# PIC16F15276 register map
File version: 1.0
PIC16F15276 special function registers
Registers are 8-bit, read-write, reset 0x0 unless marked. A register's access mark holds for its fields unless they carry their own. Offsets are from the block's base; lines under a group give offsets from that group; [hi:lo] are bit positions; {n}, {i} and the like mark numbered series; 'fields as' and 'values as' point back to an identical list; <NAME> marks a mode.

## Memory map
0x00800000 CPU size 0x1FF0 — Core registers
0x0080000C PORTA size 0x1F34
0x0080000D PORTB size 0x1F3E
0x0080000E PORTC size 0x1F48
0x0080000F PORTD size 0x1F4F
0x00800010 PORTE size 0x1F5C
0x0080009A OTHER size 0x1F4 — Other registers
0x0080009B ADC size 0x5 — Analog-to-digital converter
0x00800119 EUSART size 0x7
0x0080018C MSSP size 0x1D3C — Synchronous serial port
0x0080020C TIMER1 size 0x6
0x0080028E TIMER2 size 0x4
0x0080030C CCP size 0x1B97 — Capture, compare and PWM
0x0080059C TIMER0 size 0x4
0x0080070C INTERRUPTS size 0xD — Interrupt flags and enables
0x0080080C SYSTEM size 0x9 — Reset, watchdog and pin options
0x0080081A NVM size 0x6 — Flash and EEPROM access
0x0080088E OSCILLATOR size 0x6
0x0080090C REFERENCES size 0x1 — Voltage reference, DAC and SR latch
0x00801E8F PPS size 0xA4 — Peripheral pin select

## CPU — Core registers
Base 0x00800000
0x00 INDF0 reset not defined — INDF0, data address 0x000
0x01 INDF1 reset not defined — INDF1, data address 0x001
0x02 PCL — PCL, data address 0x002
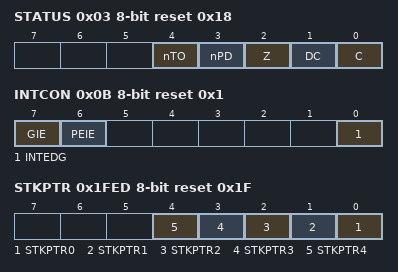
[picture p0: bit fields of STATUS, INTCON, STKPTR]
0x03 STATUS reset 0x18 — STATUS, data address 0x003
  [4] nTO, [3] nPD, [2] Z, [1] DC, [0] C
0x04 FSR0L — FSR0L, data address 0x004
0x05 FSR0H — FSR0H, data address 0x005
0x06 FSR1L — FSR1L, data address 0x006
0x07 FSR1H — FSR1H, data address 0x007
0x08 BSR — BSR, data address 0x008
  [5:0] BSR
0x09 WREG — WREG, data address 0x009
0x0A PCLATH — PCLATH, data address 0x00a
  [6:0] PCLATH
0x0B INTCON reset 0x1 — INTCON, data address 0x00b
  [7] GIE, [6] PEIE, [0] INTEDG
0x1FE4 STATUS_SHAD reset not defined — STATUS_SHAD, data address 0x1fe4
0x1FE5 WREG_SHAD reset not defined — WREG_SHAD, data address 0x1fe5
0x1FE6 BSR_SHAD reset not defined — BSR_SHAD, data address 0x1fe6
0x1FE7 PCLATH_SHAD reset not defined — PCLATH_SHAD, data address 0x1fe7
0x1FE8 FSR0L_SHAD reset not defined — FSR0L_SHAD, data address 0x1fe8
0x1FE9 FSR0H_SHAD reset not defined — FSR0H_SHAD, data address 0x1fe9
0x1FEA FSR1L_SHAD reset not defined — FSR1L_SHAD, data address 0x1fea
0x1FEB FSR1H_SHAD reset not defined — FSR1H_SHAD, data address 0x1feb
0x1FED STKPTR reset 0x1F — STKPTR, data address 0x1fed
  [n] STKPTR{n} (n=0..4)
0x1FEE TOSL reset not defined — TOSL, data address 0x1fee
0x1FEF TOSH reset not defined — TOSH, data address 0x1fef

## ADC — Analog-to-digital converter
Base 0x0080009B
0x00 ADRESL reset not defined — ADRESL, data address 0x09b
0x01 ADRESH reset not defined — ADRESH, data address 0x09c
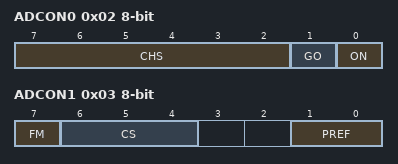
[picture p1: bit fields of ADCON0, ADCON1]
0x02 ADCON0 — ADCON0, data address 0x09d
  [7:2] CHS, [1] GO, [0] ON
0x03 ADCON1 — ADCON1, data address 0x09e
  [7] FM, [6:4] CS, [1:0] PREF
0x04 ADACT — ADACT, data address 0x09f
  [3:0] ACT

## CCP — Capture, compare and PWM
Base 0x0080030C
0x00 CCPR1L reset not defined — CCPR1L, data address 0x30c
  [7:0] CCPRL
0x01 CCPR1H reset not defined — CCPR1H, data address 0x30d
  [7:0] CCPRH
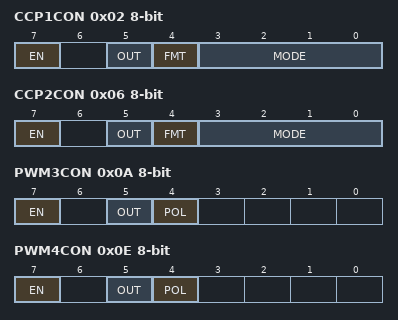
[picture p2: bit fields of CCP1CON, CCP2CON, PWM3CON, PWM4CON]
0x02 CCP1CON (reset mask 0x9F) — CCP1CON, data address 0x30e
  [7] EN, [5] OUT, [4] FMT, [3:0] MODE
0x03 CCP1CAP — CCP1CAP, data address 0x30f
  [1:0] CTS
0x04 CCPR2L reset not defined — CCPR2L, data address 0x310
  [7:0] CCPRL
0x05 CCPR2H reset not defined — CCPR2H, data address 0x311
  [7:0] CCPRH
0x06 CCP2CON (reset mask 0x9F) — CCP2CON, data address 0x312
  [7] EN, [5] OUT, [4] FMT, [3:0] MODE
0x07 CCP2CAP — CCP2CAP, data address 0x313
  [1:0] CTS
0x08 PWM3DCL reset not defined — PWM3DCL, data address 0x314
  [7:6] DCL
0x09 PWM3DCH reset not defined — PWM3DCH, data address 0x315
  [7:0] DCH
0x0A PWM3CON — PWM3CON, data address 0x316
  [7] EN, [5] OUT, [4] POL
0x0C PWM4DCL reset not defined — PWM4DCL, data address 0x318
  [7:6] DCL
0x0D PWM4DCH reset not defined — PWM4DCH, data address 0x319
  [7:0] DCH
0x0E PWM4CON — PWM4CON, data address 0x31a
  [7] EN, [5] OUT, [4] POL
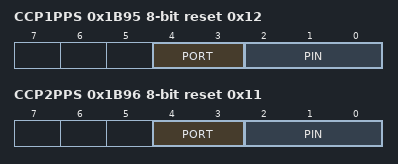
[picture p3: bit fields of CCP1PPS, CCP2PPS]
0x1B95 CCP1PPS reset 0x12 — CCP1PPS, data address 0x1ea1
  [4:3] PORT, [2:0] PIN
0x1B96 CCP2PPS reset 0x11 — CCP2PPS, data address 0x1ea2
  [4:3] PORT, [2:0] PIN
